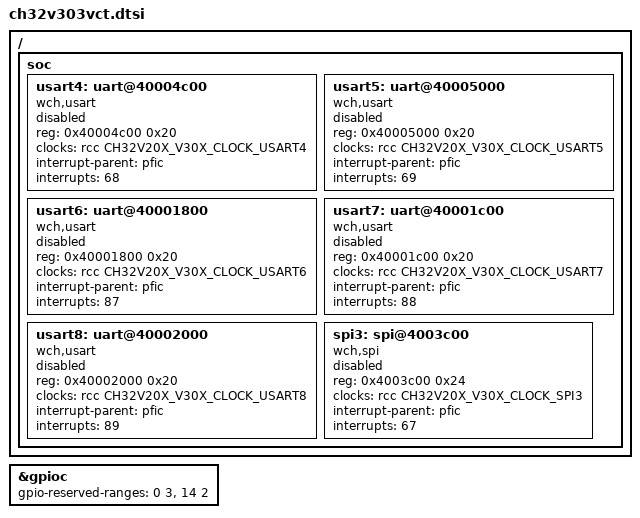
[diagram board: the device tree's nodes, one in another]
/*
 * Copyright (c) 2025 Bootlin
 *
 * SPDX-License-Identifier: Apache-2.0
 */

#include <wch/ch32v303/ch32v303.dtsi>

/ {
	soc {
		usart4: uart@40004c00 {
			compatible = "wch,usart";
			reg = <0x40004c00 0x20>;
			clocks = <&rcc CH32V20X_V30X_CLOCK_USART4>;
			interrupt-parent = <&pfic>;
			interrupts = <68>;
			status = "disabled";
		};

		usart5: uart@40005000 {
			compatible = "wch,usart";
			reg = <0x40005000 0x20>;
			clocks = <&rcc CH32V20X_V30X_CLOCK_USART5>;
			interrupt-parent = <&pfic>;
			interrupts = <69>;
			status = "disabled";
		};

		usart6: uart@40001800 {
			compatible = "wch,usart";
			reg = <0x40001800 0x20>;
			clocks = <&rcc CH32V20X_V30X_CLOCK_USART6>;
			interrupt-parent = <&pfic>;
			interrupts = <87>;
			status = "disabled";
		};

		usart7: uart@40001c00 {
			compatible = "wch,usart";
			reg = <0x40001c00 0x20>;
			clocks = <&rcc CH32V20X_V30X_CLOCK_USART7>;
			interrupt-parent = <&pfic>;
			interrupts = <88>;
			status = "disabled";
		};

		usart8: uart@40002000 {
			compatible = "wch,usart";
			reg = <0x40002000 0x20>;
			clocks = <&rcc CH32V20X_V30X_CLOCK_USART8>;
			interrupt-parent = <&pfic>;
			interrupts = <89>;
			status = "disabled";
		};

		spi3: spi@4003c00 {
			compatible = "wch,spi";
			reg = <0x4003c00 0x24>;
			clocks = <&rcc CH32V20X_V30X_CLOCK_SPI3>;
			interrupt-parent = <&pfic>;
			interrupts = <67>;
			status = "disabled";
			#address-cells = <1>;
			#size-cells = <0>;
		};
	};
};

&gpioc {
	gpio-reserved-ranges = <0 3>, <14 2>;
};
